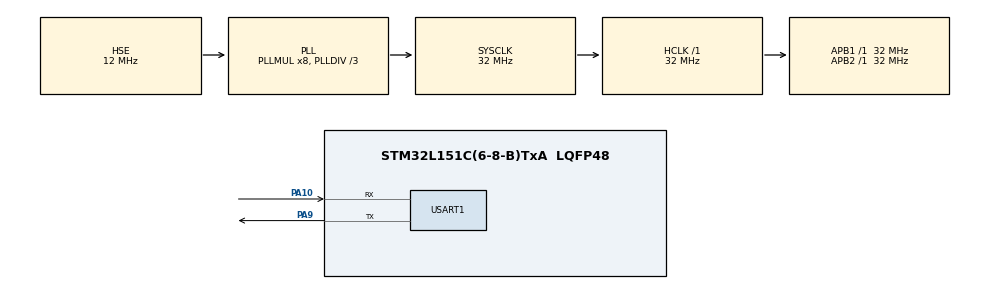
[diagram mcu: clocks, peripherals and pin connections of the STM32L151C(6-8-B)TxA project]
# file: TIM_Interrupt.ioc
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Mcu.Family=STM32L1
Mcu.Name=STM32L151C(6-8-B)TxA
Mcu.Package=LQFP48
NVIC.PriorityGroup=NVIC_PRIORITYGROUP_4
NVIC.TIM2_IRQn=true\:0\:0\:false\:false\:true\:true\:true
PA10.Mode=Asynchronous
PA10.Signal=USART1_RX
PA13.Mode=Serial_Wire
PA13.Signal=SYS_JTMS-SWDIO
PA14.Mode=Serial_Wire
PA14.Signal=SYS_JTCK-SWCLK
PA9.Mode=Asynchronous
PA9.Signal=USART1_TX
PH0-OSC_IN.Mode=HSE-External-Oscillator
PH0-OSC_IN.Signal=RCC_OSC_IN
PH1-OSC_OUT.Mode=HSE-External-Oscillator
PH1-OSC_OUT.Signal=RCC_OSC_OUT
ProjectManager.HeapSize=0x200
ProjectManager.StackSize=0x400
ProjectManager.TargetToolchain=MDK-ARM V5.27
RCC.48MHZClocksFreq_Value=48000000
RCC.AHBFreq_Value=32000000
RCC.APB1Freq_Value=32000000
RCC.APB1TimFreq_Value=32000000
RCC.APB2Freq_Value=32000000
RCC.APB2TimFreq_Value=32000000
RCC.HCLKFreq_Value=32000000
RCC.HSE_VALUE=12000000
RCC.HSI_VALUE=16000000
RCC.LSE_VALUE=32768
RCC.MSI_VALUE=2097000
RCC.PLLDIV=RCC_PLL_DIV3
RCC.PLLMUL=RCC_PLL_MUL8
RCC.PLLSourceVirtual=RCC_PLLSOURCE_HSE
RCC.SYSCLKFreq_VALUE=32000000
RCC.SYSCLKSource=RCC_SYSCLKSOURCE_PLLCLK
RCC.VCOOutputFreq_Value=96000000
TIM2.AutoReloadPreload=TIM_AUTORELOAD_PRELOAD_ENABLE
TIM2.Period=20000
TIM2.Prescaler=32-1
USART1.VirtualMode=VM_ASYNC
VP_TIM2_VS_ClockSourceINT.Mode=Internal
board=custom

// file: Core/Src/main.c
/* USER CODE BEGIN Header */
/**
  ******************************************************************************
  * @file           : main.c
  * @brief          : Main program body
  ******************************************************************************
  * @attention
  *
  * <h2><center>&copy; Copyright (c) 2020 STMicroelectronics.
  * All rights reserved.</center></h2>
  *
  * This software component is licensed by ST under BSD 3-Clause license,
  * the "License"; You may not use this file except in compliance with the
  * License. You may obtain a copy of the License at:
  *                        opensource.org/licenses/BSD-3-Clause
  *
  ******************************************************************************
  */
/* USER CODE END Header */
#include "main.h"
#include "tim.h"
#include "usart.h"
#include "gpio.h"

/* USER CODE BEGIN Includes */
#include "stdio.h"
/* USER CODE END Includes */

void SystemClock_Config(void);

int main(void)
{

  /* MCU Configuration--------------------------------------------------------*/

  /* Reset of all peripherals, Initializes the Flash interface and the Systick. */
  HAL_Init();

  /* Configure the system clock */
  SystemClock_Config();

  /* Initialize all configured peripherals */
  MX_GPIO_Init();
  MX_TIM2_Init();
  MX_USART1_UART_Init();
  /* USER CODE BEGIN 2 */
	/*使能定时器2中断*/
	HAL_TIM_Base_Start_IT(&htim2);
  /* USER CODE END 2 */

  /* Infinite loop */
  /* USER CODE BEGIN WHILE */
  while (1)
  {
		if(Flag200Ms)
		{
			printf("Hello World!");
			Flag200Ms = 0;
		}
    /* USER CODE END WHILE */

  }
}

void SystemClock_Config(void)
{
  RCC_OscInitTypeDef RCC_OscInitStruct = {0};
  RCC_ClkInitTypeDef RCC_ClkInitStruct = {0};

  /** Configure the main internal regulator output voltage
  */
  __HAL_PWR_VOLTAGESCALING_CONFIG(PWR_REGULATOR_VOLTAGE_SCALE1);
  /** Initializes the RCC Oscillators according to the specified parameters
  * in the RCC_OscInitTypeDef structure.
  */
  RCC_OscInitStruct.OscillatorType = RCC_OSCILLATORTYPE_HSE;
  RCC_OscInitStruct.HSEState = RCC_HSE_ON;
  RCC_OscInitStruct.PLL.PLLState = RCC_PLL_ON;
  RCC_OscInitStruct.PLL.PLLSource = RCC_PLLSOURCE_HSE;
  RCC_OscInitStruct.PLL.PLLMUL = RCC_PLL_MUL8;
  RCC_OscInitStruct.PLL.PLLDIV = RCC_PLL_DIV3;
  if (HAL_RCC_OscConfig(&RCC_OscInitStruct) != HAL_OK)
  {
    Error_Handler();
  }
  /** Initializes the CPU, AHB and APB buses clocks
  */
  RCC_ClkInitStruct.ClockType = RCC_CLOCKTYPE_HCLK|RCC_CLOCKTYPE_SYSCLK
                              |RCC_CLOCKTYPE_PCLK1|RCC_CLOCKTYPE_PCLK2;
  RCC_ClkInitStruct.SYSCLKSource = RCC_SYSCLKSOURCE_PLLCLK;
  RCC_ClkInitStruct.AHBCLKDivider = RCC_SYSCLK_DIV1;
  RCC_ClkInitStruct.APB1CLKDivider = RCC_HCLK_DIV1;
  RCC_ClkInitStruct.APB2CLKDivider = RCC_HCLK_DIV1;

  if (HAL_RCC_ClockConfig(&RCC_ClkInitStruct, FLASH_LATENCY_1) != HAL_OK)
  {
    Error_Handler();
  }
}

void Error_Handler(void)
{
}

/************************ (C) COPYRIGHT STMicroelectronics *****END OF FILE****/
